# f28002x_bgcrc_regs register map
Vendor: Texas Instruments
Peripheral module from a debugger description file (folder C2000).
Address unit: 16 bits
Registers are 32-bit, read-write, no defined reset value unless marked. A register's access mark holds for its fields unless they carry their own. Offsets are as the file gives them; lines under a group give offsets from that group; [hi:lo] are bit positions; {n}, {i} and the like mark numbered series; 'fields as' and 'values as' point back to an identical list; <NAME> marks a mode.

## BGCRC_REGS — BGCRC Registers
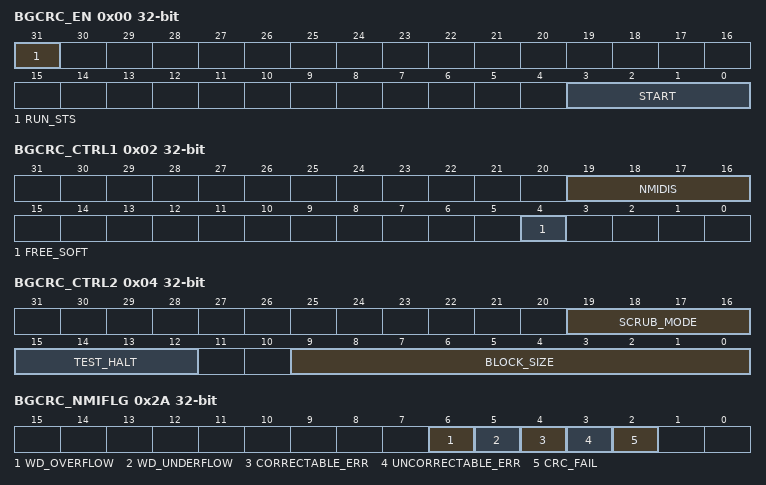
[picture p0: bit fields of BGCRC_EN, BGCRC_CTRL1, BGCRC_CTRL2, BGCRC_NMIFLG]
0x00 BGCRC_EN access per field — BGCRC Enable
  [31] RUN_STS ro — CRC module activity monitor
  [3:0] START rw — Start Bit used to Kick-off CRC calculations
0x02 BGCRC_CTRL1 — BGCRC Control register 1
  [19:16] NMIDIS — NMI disable configuration
  [4] FREE_SOFT — emulation control bit
0x04 BGCRC_CTRL2 — BGCRC Control register 2
  [19:16] SCRUB_MODE — Scrub mode configuration
  [15:12] TEST_HALT — TEST_HALT configuration
  [9:0] BLOCK_SIZE — block size for memory check
0x06 BGCRC_START_ADDR — Start address for the BGCRC check
  [31:0] START_ADDRESS
0x08 BGCRC_SEED — Seed for CRC calculation
  [31:0] SEED — Initial CRC value
0x0E BGCRC_GOLDEN — Golden CRC to be compared against
  [31:0] CRC_VALUE — Expected CRC value
0x10 BGCRC_RESULT ro — CRC calculated
  [31:0] CRC_VALUE — CRC result register
0x12 BGCRC_CURR_ADDR ro — Current address regsiter
  [31:0] CURRENT_ADDR — Current address from where the data is fetched.
0x1C BGCRC_WD_CFG — BGCRC windowed watchdog configuration
  [3:0] WDDIS — CRC Watchdog disable
0x1E BGCRC_WD_MIN — BGCRC windowed watchdog min value
  [31:0] MINVAL — Minimum value configuration for CRC windowed watchdog
0x20 BGCRC_WD_MAX — BGCRC windowed watchdog max value
  [31:0] MAXVAL — Maximum value configuration for CRC windowed watchdog
0x22 BGCRC_WD_CNT ro — BGCRC windowed watchdog count
  [31:0] WD_CNT — CRC windowed watchdog counter value
0x2A BGCRC_NMIFLG ro — BGCRC NMI flag register
  [6] WD_OVERFLOW — CRC/scrubbing did not complete within BGCRC_WD_MAX
  [5] WD_UNDERFLOW — CRC/scrubbing completed before BGCRC_WD_MIN
  [4] CORRECTABLE_ERR — Correctable ECC error obtained during memory data read.
  [3] UNCORRECTABLE_ERR — Uncorrectable error obtained during memory data read.
  [2] CRC_FAIL — CRC computation failed
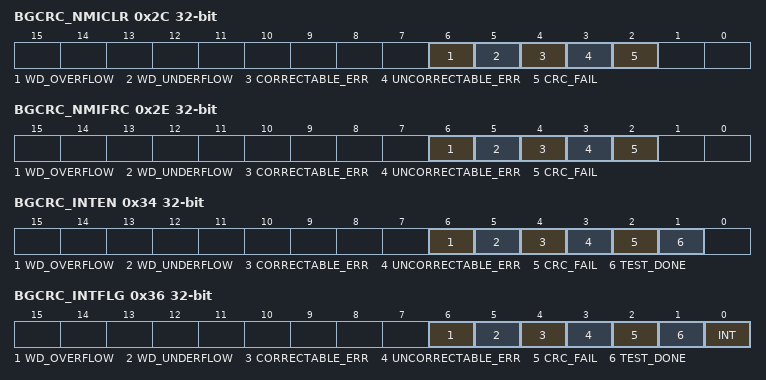
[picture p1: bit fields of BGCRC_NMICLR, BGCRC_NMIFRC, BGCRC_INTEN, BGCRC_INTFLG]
0x2C BGCRC_NMICLR — BGCRC NMI flag clear register
  [6] WD_OVERFLOW — WD_OVERFLOW NMI flag clear
  [5] WD_UNDERFLOW — WD_UNDERFLOW NMI flag clear
  [4] CORRECTABLE_ERR — CORRECTABLE_ERR NMI flag clear
  [3] UNCORRECTABLE_ERR — UNCORRECTABLE_ERR NMI flag clear
  [2] CRC_FAIL — CRC_FAIL NMI flag clear
0x2E BGCRC_NMIFRC — BGCRC NMI flag force register
  [6] WD_OVERFLOW — WD_OVERFLOW NMI force
  [5] WD_UNDERFLOW — WD_UNDERFLOW NMI force
  [4] CORRECTABLE_ERR — CORRECTABLE_ERR NMI force
  [3] UNCORRECTABLE_ERR — UNCORRECTABLE_ERR NMI force
  [2] CRC_FAIL — CRC_FAIL NMI force
0x34 BGCRC_INTEN — Interrupt enable
  [6] WD_OVERFLOW — WD_OVERFLOW interrupt enable register
  [5] WD_UNDERFLOW — WD_UNDERFLOW interrupt enable register
  [4] CORRECTABLE_ERR — CORRECTABLE_ERR interrupt enable register
  [3] UNCORRECTABLE_ERR — UNCORRECTABLE_ERR interrupt enable register
  [2] CRC_FAIL — CRC_FAIL interrupt enable register
  [1] TEST_DONE — TEST_DONE interrupt enable register
0x36 BGCRC_INTFLG ro — Interrupt flag
  [6] WD_OVERFLOW — CRC/scrubbing did not complete within BGCRC_WD_MAX
  [5] WD_UNDERFLOW — CRC/scrubbing completed before BGCRC_WD_MIN
  [4] CORRECTABLE_ERR — Correctable ECC error obtained during memory data read.
  [3] UNCORRECTABLE_ERR — Uncorrectable error obtained during memory data read.
  [2] CRC_FAIL — CRC computation failed
  [1] TEST_DONE — TEST_DONE Interrupt status flag
  [0] INT — Global Interrupt status flag
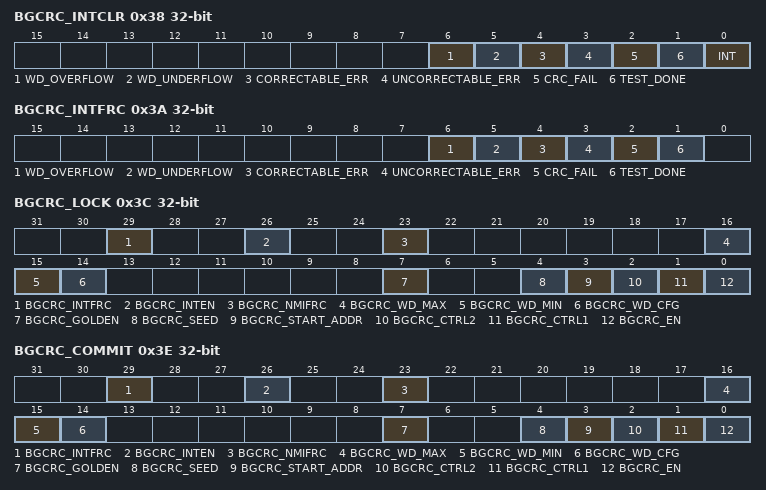
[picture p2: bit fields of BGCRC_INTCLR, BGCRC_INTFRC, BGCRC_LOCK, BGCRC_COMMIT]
0x38 BGCRC_INTCLR — Interrupt flag clear
  [6] WD_OVERFLOW — WD_OVERFLOW interrupt clear
  [5] WD_UNDERFLOW — WD_UNDERFLOW interrupt clear
  [4] CORRECTABLE_ERR — CORRECTABLE_ERR interrupt clear
  [3] UNCORRECTABLE_ERR — UNCORRECTABLE_ERR interrupt clear
  [2] CRC_FAIL — CRC_FAIL interrupt clear
  [1] TEST_DONE — TEST_DONE Interrupt clear
  [0] INT — Global Interrupt clear
0x3A BGCRC_INTFRC — Interrupt flag force
  [6] WD_OVERFLOW — WD_OVERFLOW interrupt force
  [5] WD_UNDERFLOW — WD_UNDERFLOW interrupt force
  [4] CORRECTABLE_ERR — CORRECTABLE_ERR interrupt force
  [3] UNCORRECTABLE_ERR — UNCORRECTABLE_ERR interrupt force
  [2] CRC_FAIL — CRC_FAIL interrupt force
  [1] TEST_DONE — TEST_DONE Interrupt force
0x3C BGCRC_LOCK — BGCRC register map lockconfiguration
  [29] BGCRC_INTFRC — Register lock configuration
  [26] BGCRC_INTEN — Register lock configuration
  [23] BGCRC_NMIFRC — Register lock configuration
  [16] BGCRC_WD_MAX — Register lock configuration
  [15] BGCRC_WD_MIN — Register lock configuration
  [14] BGCRC_WD_CFG — Register lock configuration
  [7] BGCRC_GOLDEN — Register lock configuration
  [4] BGCRC_SEED — Register lock configuration
  [3] BGCRC_START_ADDR — Register lock configuration
  [2] BGCRC_CTRL2 — Register lock configuration
  [1] BGCRC_CTRL1 — Register lock configuration
  [0] BGCRC_EN — Register lock configuration
0x3E BGCRC_COMMIT — BGCRC register map commit configuration
  [29] BGCRC_INTFRC — Register lock committed
  [26] BGCRC_INTEN — Register lock committed
  [23] BGCRC_NMIFRC — Register lock committed
  [16] BGCRC_WD_MAX — Register lock committed
  [15] BGCRC_WD_MIN — Register lock committed
  [14] BGCRC_WD_CFG — Register lock committed
  [7] BGCRC_GOLDEN — Register lock committed
  [4] BGCRC_SEED — Register lock committed
  [3] BGCRC_START_ADDR — Register lock committed
  [2] BGCRC_CTRL2 — Register lock committed
  [1] BGCRC_CTRL1 — Register lock committed
  [0] BGCRC_EN — Register lock committed
